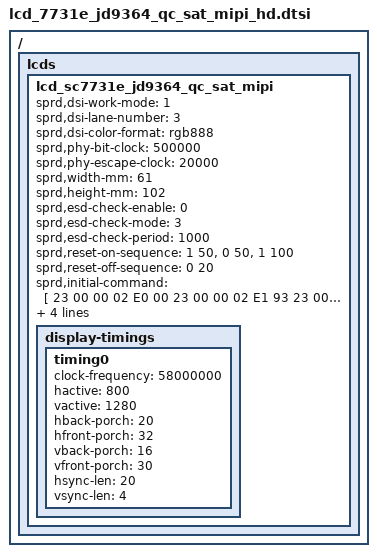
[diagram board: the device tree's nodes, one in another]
/ { lcds {
	lcd_sc7731e_jd9364_qc_sat_mipi: lcd_sc7731e_jd9364_qc_sat_mipi {

		sprd,dsi-work-mode = <1>;
		sprd,dsi-lane-number = <3>;
		sprd,dsi-color-format = "rgb888";

		sprd,phy-bit-clock = <500000>;
		sprd,phy-escape-clock = <20000>;

		sprd,width-mm = <61>;
		sprd,height-mm = <102>;

		sprd,esd-check-enable = <0>;
		sprd,esd-check-mode = <3>;
		sprd,esd-check-period = <1000>;
		/*sprd,esd-check-register = <0x0A>;*/
		/*sprd,esd-check-value = <0x9C>;*/

		sprd,reset-on-sequence = <1 50>, <0 50>, <1 100>;
		sprd,reset-off-sequence = <0 20>;

		sprd,initial-command = [
			 23  00  00  02 E0 00
			 23  00  00  02 E1 93
			 23  00  00  02 E2 65
			 23  00  00  02 E3 F8
			 23  00  00  02 80 02  //03:4-LANE; 02:3-LANE
			 23  00  00  02 E0 04
			 23  00  00  02 2D 03  //
			 23  00  00  02 E0 01
			 23  00  00  02 00 00
			 23  00  00  02 01 5C
			 23  00  00  02 03 00
			 23  00  00  02 04 68
			 23  00  00  02 17 00
			 23  00  00  02 18 D7//4.8V
			 23  00  00  02 19 01//0.3V
			 23  00  00  02 1A 00
			 23  00  00  02 1B D7  //VGMN=0
			 23  00  00  02 1C 01
			 23  00  00  02 1F 6B//VGH_REG=15.2
			 23  00  00  02 20 29//VGL_REG=-11.2   
			 23  00  00  02 21 29//VGL_REG2=-11.2
			 23  00  00  02 22 7E       
			 23  00  00  02 37 59  //SS=1BGR=1
			 23  00  00  02 35 28  //SAP
			 23  00  00  02 38 05  //JDT=101 zigzag inversion
			 23  00  00  02 39 08
			 23  00  00  02 3A 12
			 23  00  00  02 3C 7E  //SET EQ3 for TE_H
			 23  00  00  02 3D FF  //SET CHGEN_ON modify 20140806 
			 23  00  00  02 3E FF  //SET CHGEN_OFF modify 20140806 
			 23  00  00  02 3F 7F  //SET CHGEN_OFF2 modify 20140806
			 23  00  00  02 40 06  //RSO=
			 23  00  00  02 41 A0  //LN=640->1280 line
			 23  00  00  02 43 1E  //VFP=
			 23  00  00  02 44 0B  //VBP
			 23  00  00  02 55 0F  //DCDCM=1111
			 23  00  00  02 56 01
			 23  00  00  02 57 69         //AD
			 23  00  00  02 58 0A        
			 23  00  00  02 59 2A  //VCL = -2.5V  //AD
			 23  00  00  02 5A 29  //VGH = 15.2V
			 23  00  00  02 5B 15  //VGL = -11.2V
			 23  00  00  02 5C 16  //pump clk
			 23  00  00  02 5D 64  // 64
			 23  00  00  02 5E 50  // 4D
			 23  00  00  02 5F 43  // 3E
			 23  00  00  02 60 38  // 33
			 23  00  00  02 61 36  // 31
			 23  00  00  02 62 29  // 23
			 23  00  00  02 63 2F  // 2A
			 23  00  00  02 64 1B  // 16
			 23  00  00  02 65 35  // 30
			 23  00  00  02 66 35  // 31
			 23  00  00  02 67 35  // 31
			 23  00  00  02 68 53  // 50
			 23  00  00  02 69 41  // 3D
			 23  00  00  02 6A 47  // 44
			 23  00  00  02 6B 38  // 36
			 23  00  00  02 6C 34  // 30
			 23  00  00  02 6D 27  // 23
			 23  00  00  02 6E 19  // 11
			 23  00  00  02 6F 12  // 12
			 23  00  00  02 70 64  // 64
			 23  00  00  02 71 50  // 4D
			 23  00  00  02 72 43  // 3E
			 23  00  00  02 73 38  // 33
			 23  00  00  02 74 36  // 31
			 23  00  00  02 75 29  // 23
			 23  00  00  02 76 2F  // 2A
			 23  00  00  02 77 1B  // 16
			 23  00  00  02 78 35  // 30
			 23  00  00  02 79 35  // 31
			 23  00  00  02 7A 35  // 31
			 23  00  00  02 7B 53  // 50
			 23  00  00  02 7C 41  // 3D
			 23  00  00  02 7D 47  // 44
			 23  00  00  02 7E 38  // 36
			 23  00  00  02 7F 34  // 30
			 23  00  00  02 80 27  // 23
			 23  00  00  02 81 19  // 11
			 23  00  00  02 82 12  // 12
			 23  00  00  02 E0 02
			 23  00  00  02 00 53
			 23  00  00  02 01 5F   
			 23  00  00  02 02 5F 
			 23  00  00  02 03 5F 
			 23  00  00  02 04 5F 
			 23  00  00  02 05 51 
			 23  00  00  02 06 77 
			 23  00  00  02 07 57 
			 23  00  00  02 08 4F 
			 23  00  00  02 09 5F 
			 23  00  00  02 0A 4D 
			 23  00  00  02 0B 4B 
			 23  00  00  02 0C 5F 
			 23  00  00  02 0D 49 
			 23  00  00  02 0E 47 
			 23  00  00  02 0F 45 
			 23  00  00  02 10 41 
			 23  00  00  02 11 5F 
			 23  00  00  02 12 5F 
			 23  00  00  02 13 5F 
			 23  00  00  02 14 5F 
			 23  00  00  02 15 5F 
			 23  00  00  02 16 52
			 23  00  00  02 17 5F   
			 23  00  00  02 18 5F 
			 23  00  00  02 19 5F 
			 23  00  00  02 1A 5F 
			 23  00  00  02 1B 50 
			 23  00  00  02 1C 77 
			 23  00  00  02 1D 57 
			 23  00  00  02 1E 4E 
			 23  00  00  02 1F 5F 
			 23  00  00  02 20 4C 
			 23  00  00  02 21 4A 
			 23  00  00  02 22 5F 
			 23  00  00  02 23 48 
			 23  00  00  02 24 46 
			 23  00  00  02 25 44 
			 23  00  00  02 26 40 
			 23  00  00  02 27 5F 
			 23  00  00  02 28 5F 
			 23  00  00  02 29 5F 
			 23  00  00  02 2A 5F 
			 23  00  00  02 2B 5F 
			 23  00  00  02 2C 12
			 23  00  00  02 2D 1F   
			 23  00  00  02 2E 1F 
			 23  00  00  02 2F 1F 
			 23  00  00  02 30 1F 
			 23  00  00  02 31 00 
			 23  00  00  02 32 17 
			 23  00  00  02 33 17 
			 23  00  00  02 34 04 
			 23  00  00  02 35 1F 
			 23  00  00  02 36 06 
			 23  00  00  02 37 08 
			 23  00  00  02 38 1F 
			 23  00  00  02 39 0A 
			 23  00  00  02 3A 0C 
			 23  00  00  02 3B 0E 
			 23  00  00  02 3C 10 
			 23  00  00  02 3D 1F 
			 23  00  00  02 3E 1F 
			 23  00  00  02 3F 1F 
			 23  00  00  02 40 1F 
			 23  00  00  02 41 1F
			 23  00  00  02 42 13
			 23  00  00  02 43 1F   
			 23  00  00  02 44 1F 
			 23  00  00  02 45 1F 
			 23  00  00  02 46 1F 
			 23  00  00  02 47 01 
			 23  00  00  02 48 17 
			 23  00  00  02 49 17 
			 23  00  00  02 4A 05 
			 23  00  00  02 4B 1F 
			 23  00  00  02 4C 07 
			 23  00  00  02 4D 09 
			 23  00  00  02 4E 1F 
			 23  00  00  02 4F 0B 
			 23  00  00  02 50 0D 
			 23  00  00  02 51 0F 
			 23  00  00  02 52 11 
			 23  00  00  02 53 1F 
			 23  00  00  02 54 1F 
			 23  00  00  02 55 1F 
			 23  00  00  02 56 1F 
			 23  00  00  02 57 1F 
			 23  00  00  02 58 00 
			 23  00  00  02 59 00 
			 23  00  00  02 5A 00 
			 23  00  00  02 5B 10 
			 23  00  00  02 5C 04 
			 23  00  00  02 5D 40 
			 23  00  00  02 5E 00 
			 23  00  00  02 5F 00 
			 23  00  00  02 60 40 
			 23  00  00  02 61 03 
			 23  00  00  02 62 04 
			 23  00  00  02 63 70 
			 23  00  00  02 64 70 
			 23  00  00  02 65 75 
			 23  00  00  02 66 0B 
			 23  00  00  02 67 B4 
			 23  00  00  02 68 06 
			 23  00  00  02 69 70 
			 23  00  00  02 6A 70 
			 23  00  00  02 6B 04 
			 23  00  00  02 6C 00 
			 23  00  00  02 6D 04 
			 23  00  00  02 6E 00 
			 23  00  00  02 6F 88 
			 23  00  00  02 70 00 
			 23  00  00  02 71 00 
			 23  00  00  02 72 06 
			 23  00  00  02 73 7B 
			 23  00  00  02 74 00 
			 23  00  00  02 75 BC 
			 23  00  00  02 76 00 
			 23  00  00  02 77 05 
			 23  00  00  02 78 2A 
			 23  00  00  02 79 00 
			 23  00  00  02 7A 00 
			 23  00  00  02 7B 00 
			 23  00  00  02 7C 00 
			 23  00  00  02 7D 03 
			 23  00  00  02 7E 7B 
			 23  00  00  02 E0 04
			 23  00  00  02 0E 48  //Source EQ option
			 23  00  00  02 2B 2B
			 23  00  00  02 2E 44
			 23  00  00  02 E0 00
			 23  00  00  02 E6 02//WD_Timer
			 23  00  00  02 E7 06//WD_Timer

			13 78 00 01 11
			13 64 00 01 29
			];
		sprd,sleep-in-command = [
			13 0A 00 01 28
			13 78 00 01 10
			];
		sprd,sleep-out-command = [
			13 78 00 01 11
			13 64 00 01 29
			];

		display-timings {
			timing0 {
			clock-frequency = <58000000>;
			hactive = <800>;
			vactive = <1280>;
			hback-porch = <20>;
			hfront-porch = <32>;
			vback-porch = <16>;
			vfront-porch = <30>;
			hsync-len = <20>;
			vsync-len = <4>;
			};
		};
	};
};};

